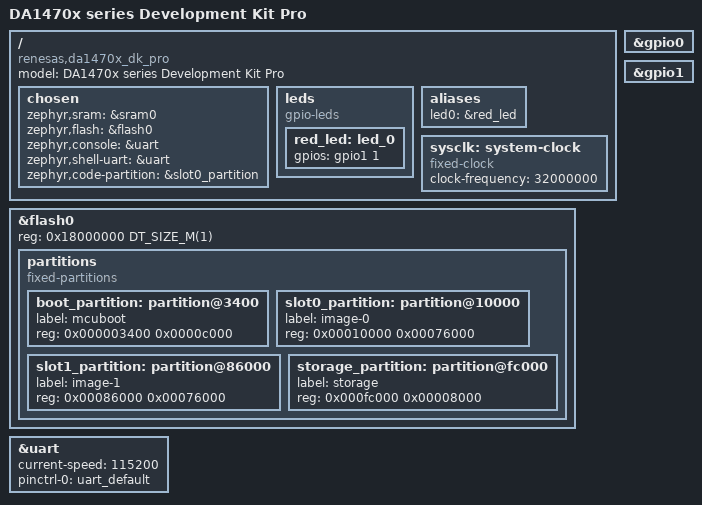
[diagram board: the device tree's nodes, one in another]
/*
 * Copyright (c) 2023 Renesas Electronics Corporation and/or its affiliates
 * SPDX-License-Identifier: Apache-2.0
 */

/dts-v1/;
#include <renesas/smartbond/da14706.dtsi>
#include "da1470x_dk_pro-pinctrl.dtsi"

/ {
	model = "DA1470x series Development Kit Pro";
	compatible = "renesas,da1470x_dk_pro";
	#address-cells = <1>;
	#size-cells = <1>;

	chosen {
		zephyr,sram = &sram0;
		zephyr,flash = &flash0;
		zephyr,console = &uart;
		zephyr,shell-uart = &uart;
        zephyr,code-partition = &slot0_partition;
	};

	
	

	leds {
		compatible = "gpio-leds";
		red_led: led_0 {
			gpios = <&gpio1 1 GPIO_ACTIVE_HIGH>;
		};
	};

	aliases {
		led0 = &red_led;
	};
	
	sysclk: system-clock {
		compatible = "fixed-clock";
		clock-frequency = <32000000>;
		#clock-cells = <0>;
	};
};


&flash0 {
	reg = <0x18000000 DT_SIZE_M(1)>;

	partitions {
		compatible = "fixed-partitions";
		#address-cells = <1>;
		#size-cells = <1>;

		/*
		 * Flash area from 0x0000 to 0x3400 is reserved
		 * for product header added by flasher.
		 */

		boot_partition: partition@3400 {
			label = "mcuboot";
			reg = <0x000003400 0x0000c000>;
		};
		slot0_partition: partition@10000 {
			label = "image-0";
			reg = <0x00010000 0x00076000>;
		};
		slot1_partition: partition@86000 {
			label = "image-1";
			reg = <0x00086000 0x00076000>;
		};
		storage_partition: partition@fc000 {
			label = "storage";
			reg = <0x000fc000 0x00008000>;
		};
	};
};

&gpio0 {
	status = "okay";
};

&gpio1 {
	status = "okay";
};

&uart {
	current-speed = <115200>;
	status = "okay";
	pinctrl-0 = <&uart_default>;
	pinctrl-names = "default";
};

// zephyr_udc0: &usbd {
// 	compatible = "renesas,smartbond-usbd";
// 	status = "okay";
// };

// &rc32m {
// 	status = "disabled";
// };

// &xtal32m {
// 	status = "okay";
// };

// &xtal32k {
// 	status = "okay";
// };

// &lp_clk {
// 	clock-src = <&xtal32k>;
// };

// &sys_clk {
// 	clock-src = <&xtal32m>;
// };

// &pll {
// 	status = "okay";
// };

&gpio0 {
	status = "okay";
};

&gpio1 {
	status = "okay";
};

&uart {
	current-speed = <115200>;
	status = "okay";
	pinctrl-0 = <&uart_default>;
	pinctrl-names = "default";
};
